# HC32M120 register map
File version: 1.0
CPU: CM0+ r0p1, little endian, no MPU, no FPU, 2 interrupt priority bits
Registers are 32-bit, read-write, reset 0x0 unless marked. A register's access mark holds for its fields unless they carry their own. Offsets are from the block's base; [hi:lo] are bit positions; {n}, {i} and the like mark numbered series; 'fields as' and 'values as' point back to an identical list.

## CRC
Base 0x40015400
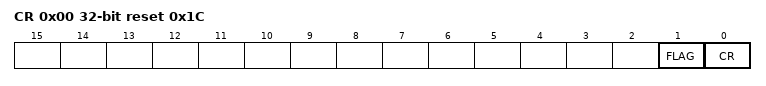
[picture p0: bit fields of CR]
0x00 CR reset 0x1C
  [1] FLAG, [0] CR
0x04 RESLT reset 0x7800
{0x80+4i} DAT{i} (i=0..31)

## CTC
Base 0x40000000
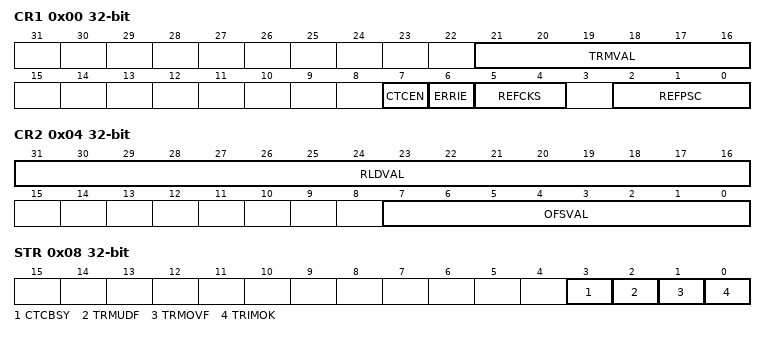
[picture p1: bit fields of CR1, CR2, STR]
0x00 CR1
  [21:16] TRMVAL, [7] CTCEN, [6] ERRIE, [5:4] REFCKS, [2:0] REFPSC
0x04 CR2
  [31:16] RLDVAL, [7:0] OFSVAL
0x08 STR ro
  [3] CTCBSY, [2] TRMUDF, [1] TRMOVF, [0] TRIMOK

## DBGC
Base 0x40015000
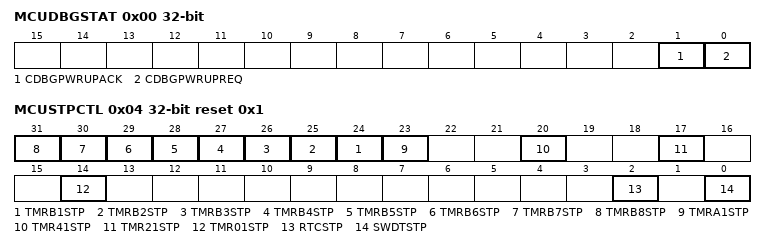
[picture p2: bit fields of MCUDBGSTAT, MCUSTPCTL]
0x00 MCUDBGSTAT
  [1] CDBGPWRUPACK, [0] CDBGPWRUPREQ
0x04 MCUSTPCTL reset 0x1 (reset mask 0xFF924001)
  [n+23] TMRB{n}STP (n=1..8), [23] TMRA1STP, [20] TMR41STP, [17] TMR21STP, [14] TMR01STP, [2] RTCSTP, [0] SWDTSTP

## DBGC_T
Base 0xE0042000
{0x0+4i} AUTHID{i} (i=0..2)
0x0C RESV0
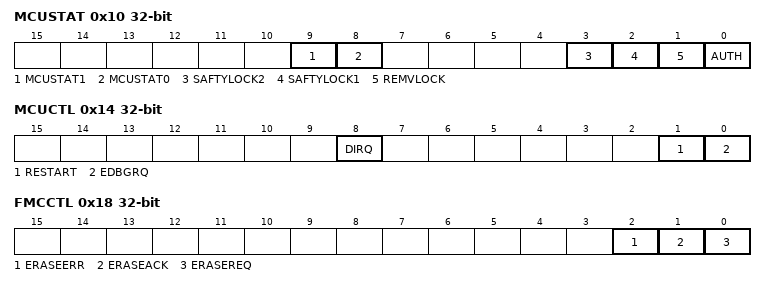
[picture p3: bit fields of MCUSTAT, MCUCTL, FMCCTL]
0x10 MCUSTAT
  [9] MCUSTAT1, [8] MCUSTAT0, [3] SAFTYLOCK2, [2] SAFTYLOCK1, [1] REMVLOCK, [0] AUTH
0x14 MCUCTL
  [8] DIRQ, [1] RESTART, [0] EDBGRQ
0x18 FMCCTL
  [2] ERASEERR, [1] ERASEACK, [0] ERASEREQ

## DMA
Base 0x40013000
0x00 EN
  [0] EN
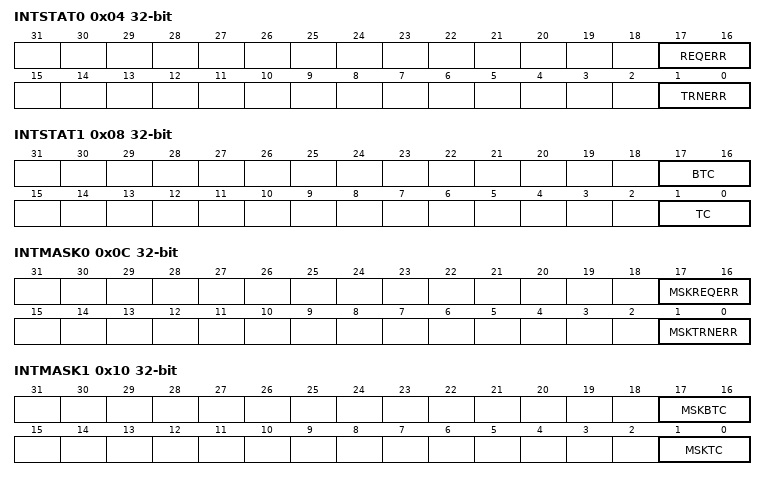
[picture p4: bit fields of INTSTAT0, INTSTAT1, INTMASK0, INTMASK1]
0x04 INTSTAT0 ro
  [17:16] REQERR, [1:0] TRNERR
0x08 INTSTAT1 ro
  [17:16] BTC, [1:0] TC
0x0C INTMASK0
  [17:16] MSKREQERR, [1:0] MSKTRNERR
0x10 INTMASK1
  [17:16] MSKBTC, [1:0] MSKTC
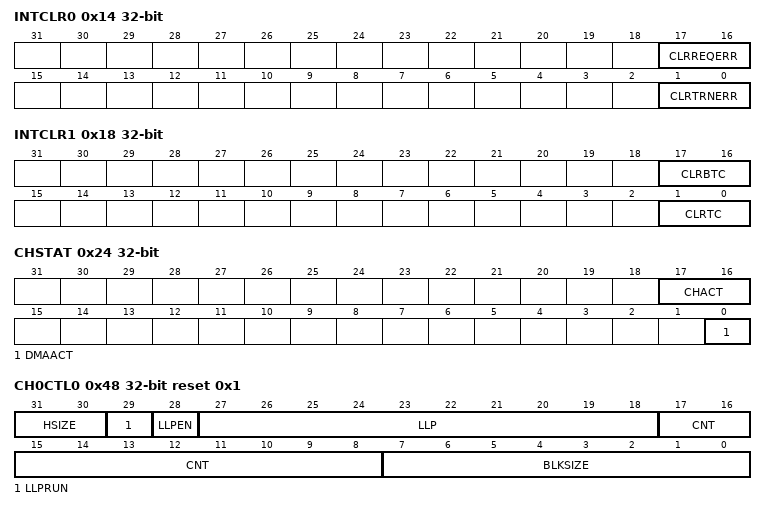
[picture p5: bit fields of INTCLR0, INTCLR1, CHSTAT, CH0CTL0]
0x14 INTCLR0 wo
  [17:16] CLRREQERR, [1:0] CLRTRNERR
0x18 INTCLR1 wo
  [17:16] CLRBTC, [1:0] CLRTC
0x1C CHEN
  [1:0] CHEN
0x24 CHSTAT ro
  [17:16] CHACT, [0] DMAACT
0x3C CHENCLR
  [1:0] CHENCLR
0x40 SAR0
0x44 DAR0
0x48 CH0CTL0 reset 0x1
  [31:30] HSIZE, [29] LLPRUN, [28] LLPEN, [27:18] LLP, [17:8] CNT, [7:0] BLKSIZE
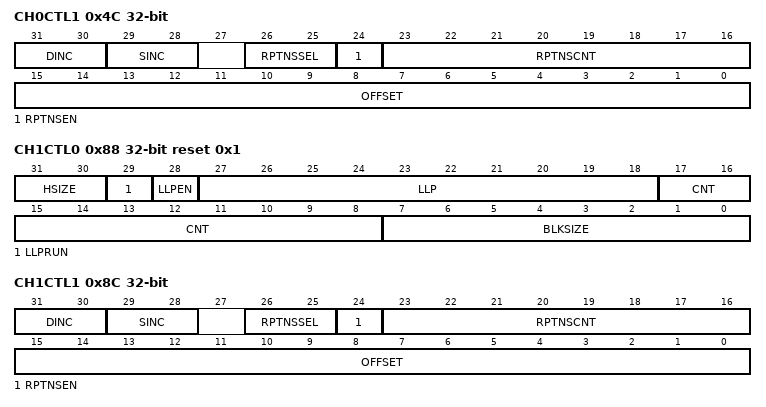
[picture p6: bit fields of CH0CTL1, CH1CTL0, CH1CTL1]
0x4C CH0CTL1
  [31:30] DINC, [29:28] SINC, [26:25] RPTNSSEL, [24] RPTNSEN, [23:16] RPTNSCNT, [15:0] OFFSET
0x80 SAR1
0x84 DAR1
0x88 CH1CTL0 reset 0x1
  fields as CH0CTL0
0x8C CH1CTL1
  fields as CH0CTL1

## EFM
Base 0x40000800
0x00 FAPRT
  [15:0] FAPRT
0x04 FSTP
  [0] FSTP
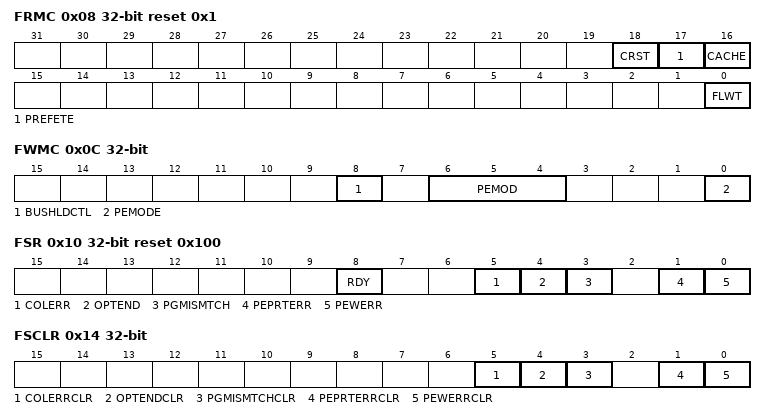
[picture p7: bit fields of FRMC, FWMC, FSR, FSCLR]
0x08 FRMC reset 0x1
  [18] CRST, [17] PREFETE, [16] CACHE, [0] FLWT
0x0C FWMC
  [8] BUSHLDCTL, [6:4] PEMOD, [0] PEMODE
0x10 FSR ro reset 0x100
  [8] RDY, [5] COLERR, [4] OPTEND, [3] PGMISMTCH, [1] PEPRTERR, [0] PEWERR
0x14 FSCLR
  [5] COLERRCLR, [4] OPTENDCLR, [3] PGMISMTCHCLR, [1] PEPRTERRCLR, [0] PEWERRCLR
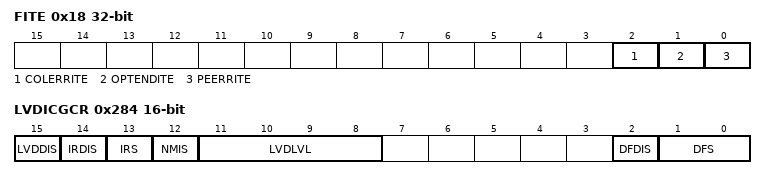
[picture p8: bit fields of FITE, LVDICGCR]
0x18 FITE
  [2] COLERRITE, [1] OPTENDITE, [0] PEERRITE
0x20 FPMTSW
  [14:0] FPMTSW
0x24 FPMTEW
  [14:0] FPMTEW
{0x50+4i} UQID{i} ro (i=0..2)
0x282 HRCCFGR 8-bit
  [3:0] HRCFREQS
0x284 LVDICGCR 16-bit reset not defined
  [15] LVDDIS, [14] IRDIS, [13] IRS, [12] NMIS, [11:8] LVDLVL, [2] DFDIS, [1:0] DFS

## EMB
Base 0x40006C00
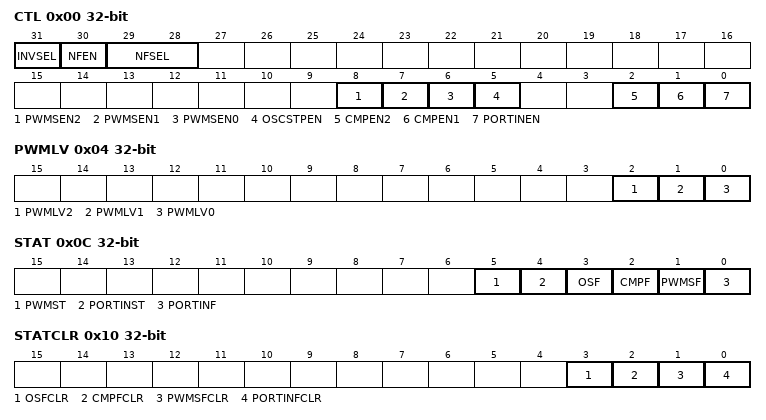
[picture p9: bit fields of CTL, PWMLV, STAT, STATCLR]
0x00 CTL
  [31] INVSEL, [30] NFEN, [29:28] NFSEL, [8] PWMSEN2, [7] PWMSEN1, [6] PWMSEN0, [5] OSCSTPEN, [2] CMPEN2, [1] CMPEN1, [0] PORTINEN
0x04 PWMLV
  [2] PWMLV2, [1] PWMLV1, [0] PWMLV0
0x08 SOE
  [0] SOE
0x0C STAT ro
  [5] PWMST, [4] PORTINST, [3] OSF, [2] CMPF, [1] PWMSF, [0] PORTINF
0x10 STATCLR wo
  [3] OSFCLR, [2] CMPFCLR, [1] PWMSFCLR, [0] PORTINFCLR
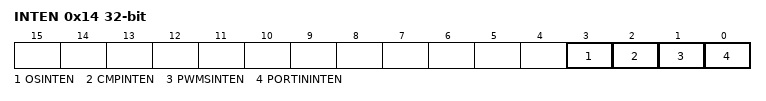
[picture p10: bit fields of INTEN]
0x14 INTEN
  [3] OSINTEN, [2] CMPINTEN, [1] PWMSINTEN, [0] PORTININTEN

## GPIO
Base 0x40013800
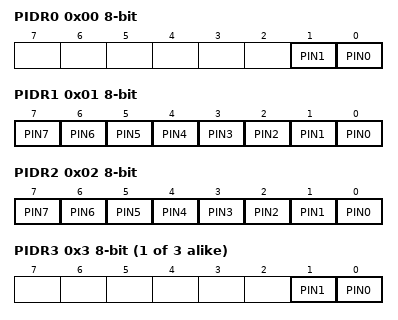
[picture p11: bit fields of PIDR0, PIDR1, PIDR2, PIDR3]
0x00 PIDR0 8-bit ro
  [1] PIN1, [0] PIN0
0x01 PIDR1 8-bit ro
  [n] PIN{n} (n=0..7)
0x02 PIDR2 8-bit ro
  [n] PIN{n} (n=0..7)
{0x0+i} PIDR{i} 8-bit ro (i=3..5)
  [1] PIN1, [0] PIN0
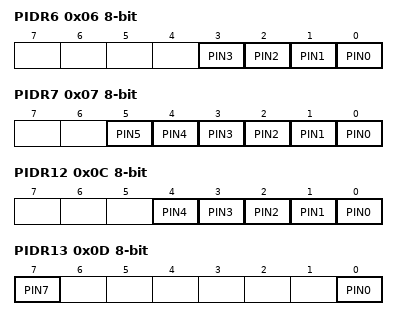
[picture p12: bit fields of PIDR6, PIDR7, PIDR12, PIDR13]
0x06 PIDR6 8-bit ro
  [n] PIN{n} (n=0..3)
0x07 PIDR7 8-bit ro
  [n] PIN{n} (n=0..5)
0x0C PIDR12 8-bit ro
  [n] PIN{n} (n=0..4)
0x0D PIDR13 8-bit ro
  [7] PIN7, [0] PIN0
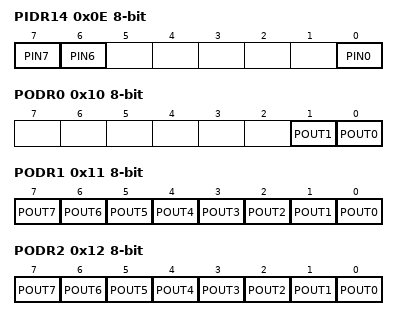
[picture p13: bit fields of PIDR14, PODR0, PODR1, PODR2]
0x0E PIDR14 8-bit ro
  [7] PIN7, [6] PIN6, [0] PIN0
0x10 PODR0 8-bit
  [1] POUT1, [0] POUT0
0x11 PODR1 8-bit
  [n] POUT{n} (n=0..7)
0x12 PODR2 8-bit
  [n] POUT{n} (n=0..7)
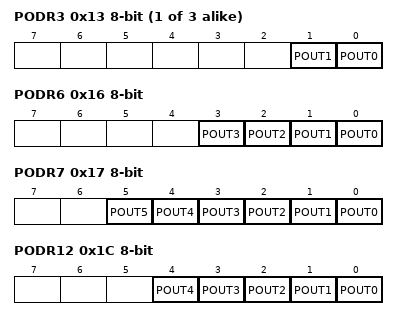
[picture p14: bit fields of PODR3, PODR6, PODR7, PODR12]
{0x10+i} PODR{i} 8-bit (i=3..5)
  [1] POUT1, [0] POUT0
0x16 PODR6 8-bit
  [n] POUT{n} (n=0..3)
0x17 PODR7 8-bit
  [n] POUT{n} (n=0..5)
0x1C PODR12 8-bit
  [n] POUT{n} (n=0..4)
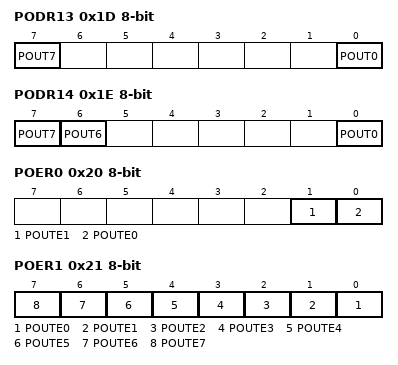
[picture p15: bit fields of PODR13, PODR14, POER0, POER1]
0x1D PODR13 8-bit
  [7] POUT7, [0] POUT0
0x1E PODR14 8-bit
  [7] POUT7, [6] POUT6, [0] POUT0
0x20 POER0 8-bit
  [1] POUTE1, [0] POUTE0
0x21 POER1 8-bit
  [n] POUTE{n} (n=0..7)
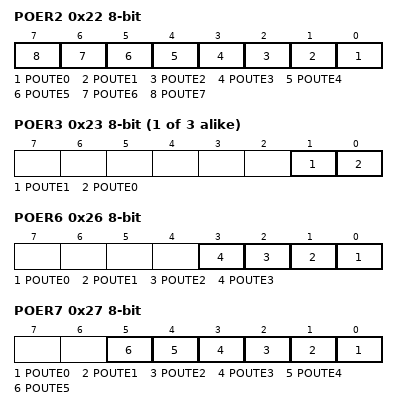
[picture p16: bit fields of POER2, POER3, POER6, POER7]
0x22 POER2 8-bit
  [n] POUTE{n} (n=0..7)
{0x20+i} POER{i} 8-bit (i=3..5)
  [1] POUTE1, [0] POUTE0
0x26 POER6 8-bit
  [n] POUTE{n} (n=0..3)
0x27 POER7 8-bit
  [n] POUTE{n} (n=0..5)
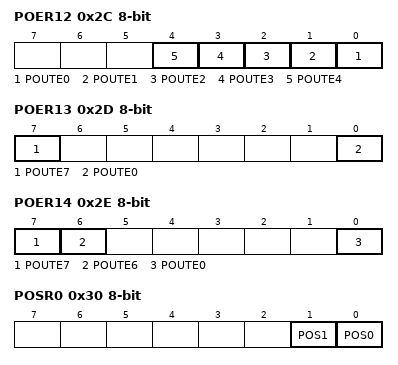
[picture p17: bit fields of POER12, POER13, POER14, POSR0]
0x2C POER12 8-bit
  [n] POUTE{n} (n=0..4)
0x2D POER13 8-bit
  [7] POUTE7, [0] POUTE0
0x2E POER14 8-bit
  [7] POUTE7, [6] POUTE6, [0] POUTE0
0x30 POSR0 8-bit wo
  [1] POS1, [0] POS0
0x31 POSR1 8-bit wo
  [n] POS{n} (n=0..7)
0x32 POSR2 8-bit wo
  [n] POS{n} (n=0..7)
{0x30+i} POSR{i} 8-bit wo (i=3..5)
  [1] POS1, [0] POS0
0x36 POSR6 8-bit wo
  [n] POS{n} (n=0..3)
0x37 POSR7 8-bit wo
  [n] POS{n} (n=0..5)
0x3C POSR12 8-bit wo
  [n] POS{n} (n=0..4)
0x3D POSR13 8-bit wo
  [7] POS7, [0] POS0
0x3E POSR14 8-bit wo
  [7] POS7, [6] POS6, [0] POS0
0x40 PORR0 8-bit wo
  [1] POR1, [0] POR0
0x41 PORR1 8-bit wo
  [n] POR{n} (n=0..7)
0x42 PORR2 8-bit wo
  [n] POR{n} (n=0..7)
{0x40+i} PORR{i} 8-bit wo (i=3..5)
  [1] POR1, [0] POR0
0x46 PORR6 8-bit wo
  [n] POR{n} (n=0..3)
0x47 PORR7 8-bit wo
  [n] POR{n} (n=0..5)
0x4C PORR12 8-bit wo
  [n] POR{n} (n=0..4)
0x4D PORR13 8-bit wo
  [7] POR7, [0] POR0
0x4E PORR14 8-bit wo
  [7] POR7, [6] POR6, [0] POR0
0x50 POTR0 8-bit wo
  [1] POT1, [0] POT0
0x51 POTR1 8-bit wo
  [n] POT{n} (n=0..7)
0x52 POTR2 8-bit wo
  [n] POT{n} (n=0..7)
{0x50+i} POTR{i} 8-bit wo (i=3..5)
  [1] POT1, [0] POT0
0x56 POTR6 8-bit wo
  [n] POT{n} (n=0..3)
0x57 POTR7 8-bit wo
  [n] POT{n} (n=0..5)
0x5C POTR12 8-bit wo
  [n] POT{n} (n=0..4)
0x5D POTR13 8-bit wo
  [7] POT7, [0] POT0
0x5E POTR14 8-bit wo
  [7] POT7, [6] POT6, [0] POT0
0x400 PCR00 16-bit
  [14:12] FSEL, [11] INTE, [10] CINSEL, [9] INVE, [8] PIN ro, [6] PUU, [5] LTE, [4] DRV, [2] NOD, [1] POUTE, [0] POUT
0x402 PCR01 16-bit
  fields as PCR00
{0x3FC+2i} PCR{i} 16-bit (i=10..17)
  fields as PCR00
{0x3F8+2i} PCR{i} 16-bit (i=20..27)
  fields as PCR00
0x430 PCR30 16-bit
  fields as PCR00
0x432 PCR31 16-bit
  fields as PCR00
0x440 PCR40 16-bit
  fields as PCR00
0x442 PCR41 16-bit
  fields as PCR00
0x450 PCR50 16-bit
  fields as PCR00
0x452 PCR51 16-bit
  fields as PCR00
{0x3E8+2i} PCR{i} 16-bit (i=60..63)
  fields as PCR00
{0x3E4+2i} PCR{i} 16-bit (i=70..75)
  fields as PCR00
{0x3D0+2i} PCR{i} 16-bit (i=120..124)
  fields as PCR00
0x4D0 PCR130 16-bit
  fields as PCR00
0x4DE PCR137 16-bit
  fields as PCR00
0x4E0 PCR140 16-bit
  fields as PCR00
0x4EC PCR146 16-bit
  fields as PCR00
0x4EE PCR147 16-bit
  fields as PCR00
0x500 PSPCR 16-bit reset 0x3
  [1:0] SPFE
0x504 PCCR 16-bit reset 0x4000
  [15:14] RDWT
0x506 PINAER 16-bit
  [14] PINAE14, [13] PINAE13, [12] PINAE12, [n] PINAE{n} (n=0..7)
0x508 PWPR 16-bit
  [15:8] WP wo, [0] WE
